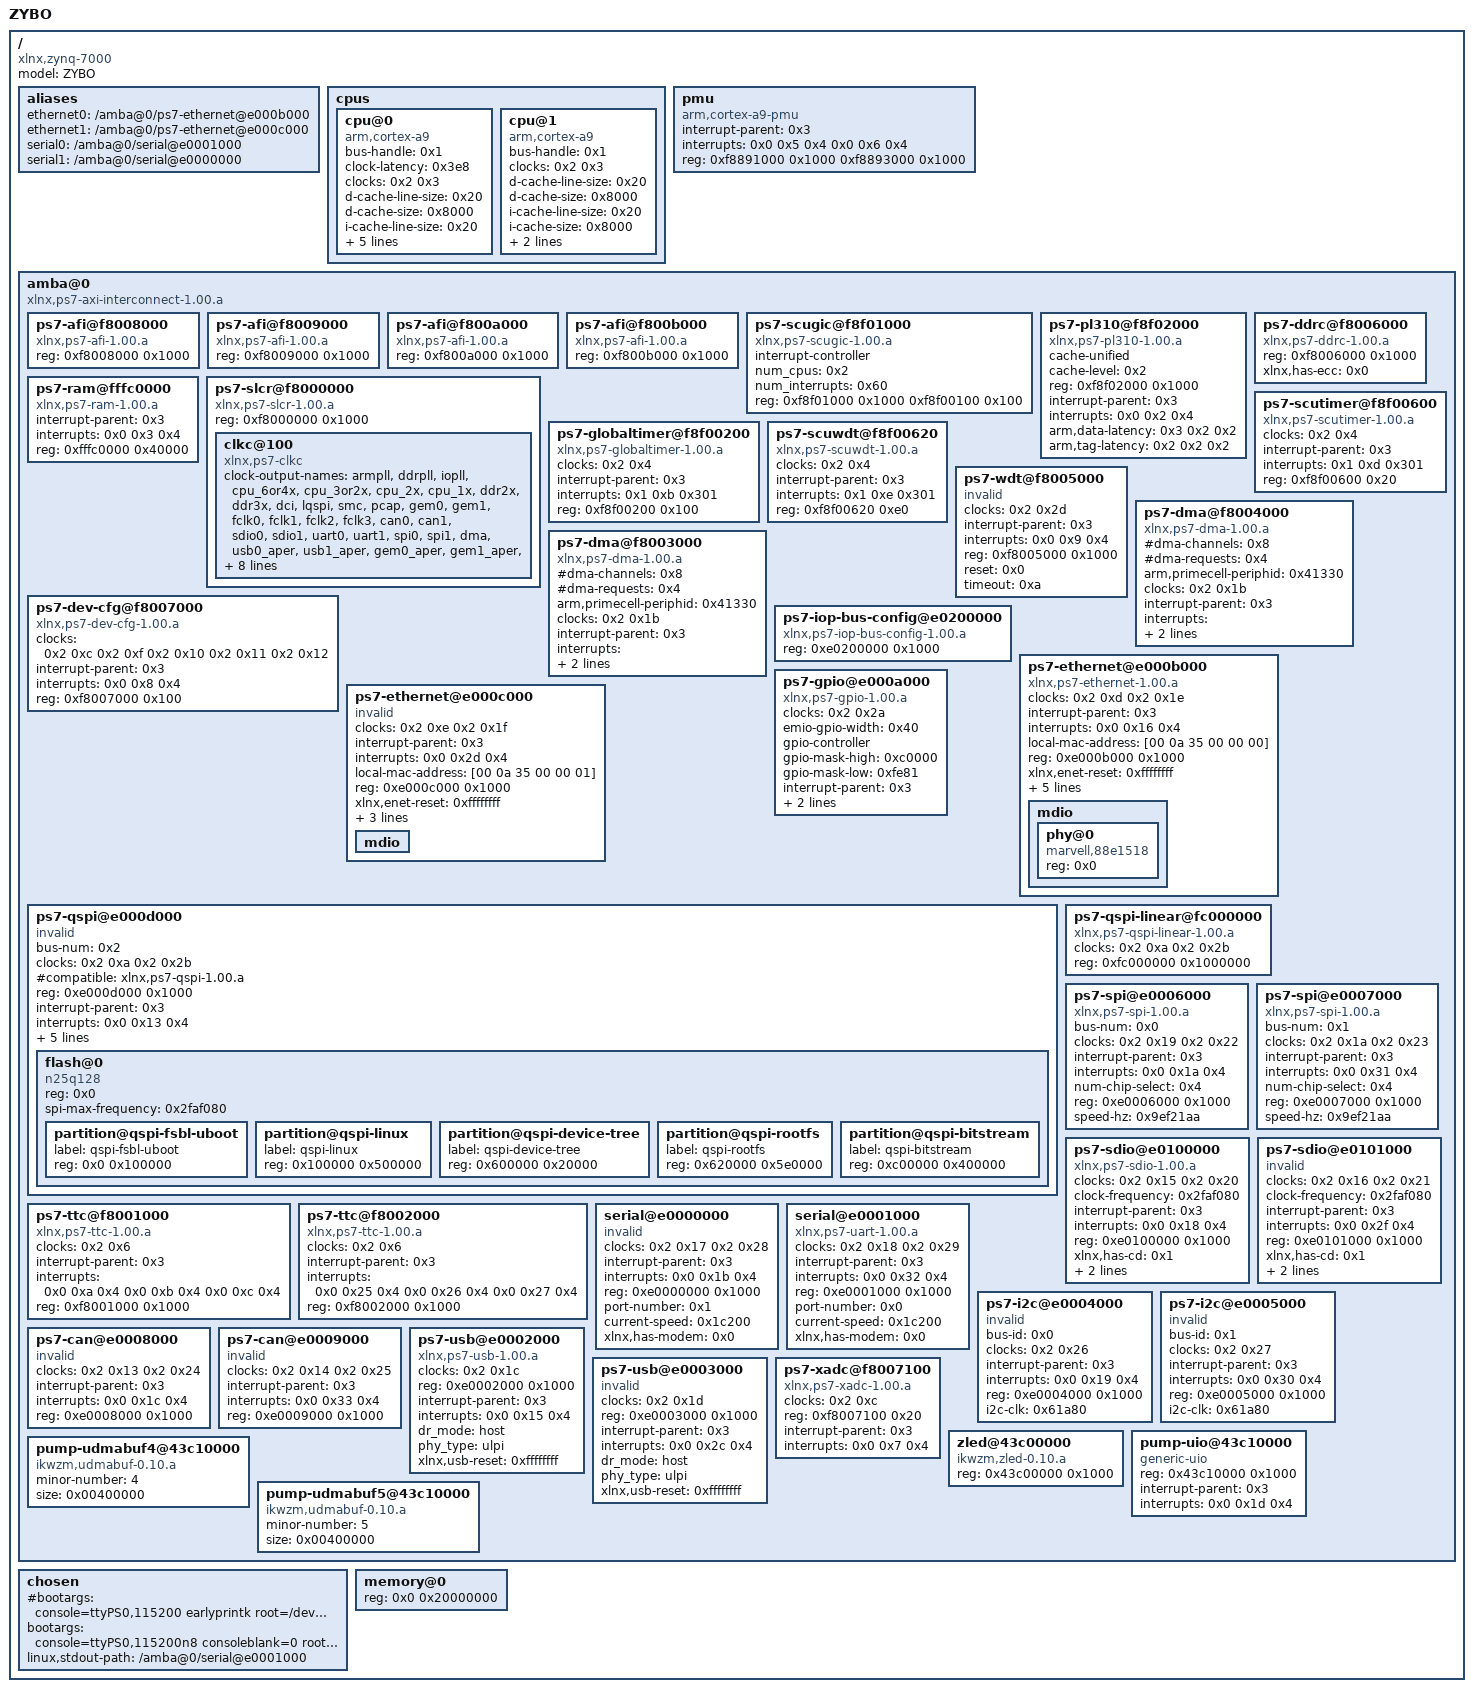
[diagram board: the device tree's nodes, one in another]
/dts-v1/;

/ {
	#address-cells = <0x1>;
	#size-cells = <0x1>;
	compatible = "xlnx,zynq-7000";
	model = "ZYBO";

	aliases {
		ethernet0 = "/amba@0/ps7-ethernet@e000b000";
		ethernet1 = "/amba@0/ps7-ethernet@e000c000";
		serial0 = "/amba@0/serial@e0001000";
		serial1 = "/amba@0/serial@e0000000";
	};

	cpus {
		#address-cells = <0x1>;
		#size-cells = <0x0>;

		cpu@0 {
			bus-handle = <0x1>;
			clock-latency = <0x3e8>;
			clocks = <0x2 0x3>;
			compatible = "arm,cortex-a9";
			d-cache-line-size = <0x20>;
			d-cache-size = <0x8000>;
			device_type = "cpu";
			i-cache-line-size = <0x20>;
			i-cache-size = <0x8000>;
			interrupt-handle = <0x3>;
			operating-points = <0xa2c2b 0xf4240 0x51616 0xf4240 0x3640f 0xf4240>;
			reg = <0x0>;
		};

		cpu@1 {
			bus-handle = <0x1>;
			clocks = <0x2 0x3>;
			compatible = "arm,cortex-a9";
			d-cache-line-size = <0x20>;
			d-cache-size = <0x8000>;
			device_type = "cpu";
			i-cache-line-size = <0x20>;
			i-cache-size = <0x8000>;
			interrupt-handle = <0x3>;
			reg = <0x1>;
		};
	};

	pmu {
		compatible = "arm,cortex-a9-pmu";
		interrupt-parent = <0x3>;
		interrupts = <0x0 0x5 0x4 0x0 0x6 0x4>;
		reg = <0xf8891000 0x1000 0xf8893000 0x1000>;
		reg-names = "cpu0", "cpu1";
	};

	amba@0 {
		#address-cells = <0x1>;
		#size-cells = <0x1>;
		compatible = "xlnx,ps7-axi-interconnect-1.00.a", "simple-bus";
		ranges;
		linux,phandle = <0x1>;
		phandle = <0x1>;

		ps7-afi@f8008000 {
			compatible = "xlnx,ps7-afi-1.00.a";
			reg = <0xf8008000 0x1000>;
		};

		ps7-afi@f8009000 {
			compatible = "xlnx,ps7-afi-1.00.a";
			reg = <0xf8009000 0x1000>;
		};

		ps7-afi@f800a000 {
			compatible = "xlnx,ps7-afi-1.00.a";
			reg = <0xf800a000 0x1000>;
		};

		ps7-afi@f800b000 {
			compatible = "xlnx,ps7-afi-1.00.a";
			reg = <0xf800b000 0x1000>;
		};

		ps7-scugic@f8f01000 {
			#address-cells = <0x2>;
			#interrupt-cells = <0x3>;
			#size-cells = <0x1>;
			compatible = "xlnx,ps7-scugic-1.00.a", "arm,cortex-a9-gic", "arm,gic";
			interrupt-controller;
			num_cpus = <0x2>;
			num_interrupts = <0x60>;
			reg = <0xf8f01000 0x1000 0xf8f00100 0x100>;
			linux,phandle = <0x3>;
			phandle = <0x3>;
		};

		ps7-pl310@f8f02000 {
			compatible = "xlnx,ps7-pl310-1.00.a", "arm,pl310-cache";
			cache-unified;
			cache-level = <0x2>;
			reg = <0xf8f02000 0x1000>;
			interrupt-parent = <0x3>;
			interrupts = <0x0 0x2 0x4>;
			arm,data-latency = <0x3 0x2 0x2>;
			arm,tag-latency = <0x2 0x2 0x2>;
		};

		ps7-ddrc@f8006000 {
			compatible = "xlnx,ps7-ddrc-1.00.a", "xlnx,ps7-ddrc";
			reg = <0xf8006000 0x1000>;
			xlnx,has-ecc = <0x0>;
		};

		ps7-ram@fffc0000 {
			compatible = "xlnx,ps7-ram-1.00.a", "xlnx,ps7-ocm";
			interrupt-parent = <0x3>;
			interrupts = <0x0 0x3 0x4>;
			reg = <0xfffc0000 0x40000>;
		};

		ps7-slcr@f8000000 {
			#address-cells = <0x1>;
			#size-cells = <0x1>;
			compatible = "xlnx,ps7-slcr-1.00.a", "xlnx,zynq-slcr", "syscon";
			ranges;
			reg = <0xf8000000 0x1000>;

			clkc@100 {
				#clock-cells = <0x1>;
				clock-output-names = "armpll", "ddrpll", "iopll", "cpu_6or4x", "cpu_3or2x", "cpu_2x", "cpu_1x", "ddr2x", "ddr3x", "dci", "lqspi", "smc", "pcap", "gem0", "gem1", "fclk0", "fclk1", "fclk2", "fclk3", "can0", "can1", "sdio0", "sdio1", "uart0", "uart1", "spi0", "spi1", "dma", "usb0_aper", "usb1_aper", "gem0_aper", "gem1_aper", "sdio0_aper", "sdio1_aper", "spi0_aper", "spi1_aper", "can0_aper", "can1_aper", "i2c0_aper", "i2c1_aper", "uart0_aper", "uart1_aper", "gpio_aper", "lqspi_aper", "smc_aper", "swdt", "dbg_trc", "dbg_apb";
				compatible = "xlnx,ps7-clkc";
				fclk-enable = <0xf>;
				ps-clk-frequency = <0x2faf080>;
				reg = <0x100 0x100>;
				linux,phandle = <0x2>;
				phandle = <0x2>;
			};
		};

		ps7-globaltimer@f8f00200 {
			clocks = <0x2 0x4>;
			compatible = "xlnx,ps7-globaltimer-1.00.a", "arm,cortex-a9-global-timer";
			interrupt-parent = <0x3>;
			interrupts = <0x1 0xb 0x301>;
			reg = <0xf8f00200 0x100>;
		};

		ps7-scutimer@f8f00600 {
			clocks = <0x2 0x4>;
			compatible = "xlnx,ps7-scutimer-1.00.a", "arm,cortex-a9-twd-timer";
			interrupt-parent = <0x3>;
			interrupts = <0x1 0xd 0x301>;
			reg = <0xf8f00600 0x20>;
		};

		ps7-scuwdt@f8f00620 {
			clocks = <0x2 0x4>;
			compatible = "xlnx,ps7-scuwdt-1.00.a";
			device_type = "watchdog";
			interrupt-parent = <0x3>;
			interrupts = <0x1 0xe 0x301>;
			reg = <0xf8f00620 0xe0>;
		};

		ps7-wdt@f8005000 {
			clocks = <0x2 0x2d>;
			compatible = "invalid";
			device_type = "watchdog";
			interrupt-parent = <0x3>;
			interrupts = <0x0 0x9 0x4>;
			reg = <0xf8005000 0x1000>;
			reset = <0x0>;
			timeout = <0xa>;
		};

		ps7-dma@f8004000 {
			#dma-cells = <0x1>;
			#dma-channels = <0x8>;
			#dma-requests = <0x4>;
			arm,primecell-periphid = <0x41330>;
			clock-names = "apb_pclk";
			clocks = <0x2 0x1b>;
			compatible = "xlnx,ps7-dma-1.00.a", "arm,primecell", "arm,pl330";
			interrupt-parent = <0x3>;
			interrupt-names = "abort", "dma0", "dma1", "dma2", "dma3", "dma4", "dma5", "dma6", "dma7";
			interrupts = <0x0 0xd 0x4 0x0 0xe 0x4 0x0 0xf 0x4 0x0 0x10 0x4 0x0 0x11 0x4 0x0 0x28 0x4 0x0 0x29 0x4 0x0 0x2a 0x4 0x0 0x2b 0x4>;
			reg = <0xf8004000 0x1000>;
		};

		ps7-dma@f8003000 {
			#dma-cells = <0x1>;
			#dma-channels = <0x8>;
			#dma-requests = <0x4>;
			arm,primecell-periphid = <0x41330>;
			clock-names = "apb_pclk";
			clocks = <0x2 0x1b>;
			compatible = "xlnx,ps7-dma-1.00.a", "arm,primecell", "arm,pl330";
			interrupt-parent = <0x3>;
			interrupt-names = "abort", "dma0", "dma1", "dma2", "dma3", "dma4", "dma5", "dma6", "dma7";
			interrupts = <0x0 0xd 0x4 0x0 0xe 0x4 0x0 0xf 0x4 0x0 0x10 0x4 0x0 0x11 0x4 0x0 0x28 0x4 0x0 0x29 0x4 0x0 0x2a 0x4 0x0 0x2b 0x4>;
			reg = <0xf8003000 0x1000>;
		};

		ps7-dev-cfg@f8007000 {
			clock-names = "ref_clk", "fclk0", "fclk1", "fclk2", "fclk3";
			clocks = <0x2 0xc 0x2 0xf 0x2 0x10 0x2 0x11 0x2 0x12>;
			compatible = "xlnx,ps7-dev-cfg-1.00.a";
			interrupt-parent = <0x3>;
			interrupts = <0x0 0x8 0x4>;
			reg = <0xf8007000 0x100>;
		};

		ps7-iop-bus-config@e0200000 {
			compatible = "xlnx,ps7-iop-bus-config-1.00.a";
			reg = <0xe0200000 0x1000>;
		};

		ps7-ethernet@e000b000 {
			#address-cells = <0x1>;
			#size-cells = <0x0>;
			clock-names = "ref_clk", "aper_clk";
			clocks = <0x2 0xd 0x2 0x1e>;
			compatible = "xlnx,ps7-ethernet-1.00.a";
			interrupt-parent = <0x3>;
			interrupts = <0x0 0x16 0x4>;
			local-mac-address = [00 0a 35 00 00 00];
			reg = <0xe000b000 0x1000>;
			xlnx,enet-reset = <0xffffffff>;
			xlnx,eth-mode = <0x1>;
			xlnx,has-mdio = <0x1>;
			xlnx,ptp-enet-clock = <0x69f6bcb>;
			phy-handle = <0x4>;
			phy-mode = "rgmii-id";

			mdio {
				#address-cells = <0x1>;
				#size-cells = <0x0>;

				phy@0 {
					compatible = "marvell,88e1518";
					device_type = "ethernet-phy";
					reg = <0x0>;
					linux,phandle = <0x4>;
					phandle = <0x4>;
				};
			};
		};

		ps7-ethernet@e000c000 {
			#address-cells = <0x1>;
			#size-cells = <0x0>;
			clock-names = "ref_clk", "aper_clk";
			clocks = <0x2 0xe 0x2 0x1f>;
			compatible = "invalid";
			interrupt-parent = <0x3>;
			interrupts = <0x0 0x2d 0x4>;
			local-mac-address = [00 0a 35 00 00 01];
			reg = <0xe000c000 0x1000>;
			xlnx,enet-reset = <0xffffffff>;
			xlnx,eth-mode = <0x1>;
			xlnx,has-mdio = <0x1>;
			xlnx,ptp-enet-clock = <0x69f6bcb>;

			mdio {
				#address-cells = <0x1>;
				#size-cells = <0x0>;
			};
		};

		ps7-gpio@e000a000 {
			#gpio-cells = <0x2>;
			clocks = <0x2 0x2a>;
			compatible = "xlnx,ps7-gpio-1.00.a";
			emio-gpio-width = <0x40>;
			gpio-controller;
			gpio-mask-high = <0xc0000>;
			gpio-mask-low = <0xfe81>;
			interrupt-parent = <0x3>;
			interrupts = <0x0 0x14 0x4>;
			reg = <0xe000a000 0x1000>;
		};

		ps7-qspi@e000d000 {
			bus-num = <0x2>;
			clock-names = "ref_clk", "aper_clk";
			clocks = <0x2 0xa 0x2 0x2b>;
			#compatible = "xlnx,ps7-qspi-1.00.a";
			compatible = "invalid";
			reg = <0xe000d000 0x1000>;
			interrupt-parent = <0x3>;
			interrupts = <0x0 0x13 0x4>;
			is-dual = <0x0>;
			num-chip-select = <0x1>;
			speed-hz = <0xbebc200>;
			xlnx,fb-clk = <0x1>;
			xlnx,qspi-mode = <0x0>;
			#address-cells = <0x1>;
			#size-cells = <0x0>;

			flash@0 {
				compatible = "n25q128";
				reg = <0x0>;
				spi-max-frequency = <0x2faf080>;
				#address-cells = <0x1>;
				#size-cells = <0x1>;

				partition@qspi-fsbl-uboot {
					label = "qspi-fsbl-uboot";
					reg = <0x0 0x100000>;
				};

				partition@qspi-linux {
					label = "qspi-linux";
					reg = <0x100000 0x500000>;
				};

				partition@qspi-device-tree {
					label = "qspi-device-tree";
					reg = <0x600000 0x20000>;
				};

				partition@qspi-rootfs {
					label = "qspi-rootfs";
					reg = <0x620000 0x5e0000>;
				};

				partition@qspi-bitstream {
					label = "qspi-bitstream";
					reg = <0xc00000 0x400000>;
				};
			};
		};

		ps7-qspi-linear@fc000000 {
			clock-names = "ref_clk", "aper_clk";
			clocks = <0x2 0xa 0x2 0x2b>;
			compatible = "xlnx,ps7-qspi-linear-1.00.a";
			reg = <0xfc000000 0x1000000>;
		};

		ps7-spi@e0006000 {
			bus-num = <0x0>;
			clock-names = "ref_clk", "aper_clk";
			clocks = <0x2 0x19 0x2 0x22>;
			compatible = "xlnx,ps7-spi-1.00.a";
			interrupt-parent = <0x3>;
			interrupts = <0x0 0x1a 0x4>;
			num-chip-select = <0x4>;
			reg = <0xe0006000 0x1000>;
			speed-hz = <0x9ef21aa>;
			#address-cells = <0x1>;
			#size-cells = <0x0>;
		};

		ps7-spi@e0007000 {
			bus-num = <0x1>;
			clock-names = "ref_clk", "aper_clk";
			clocks = <0x2 0x1a 0x2 0x23>;
			compatible = "xlnx,ps7-spi-1.00.a";
			interrupt-parent = <0x3>;
			interrupts = <0x0 0x31 0x4>;
			num-chip-select = <0x4>;
			reg = <0xe0007000 0x1000>;
			speed-hz = <0x9ef21aa>;
			#address-cells = <0x1>;
			#size-cells = <0x0>;
		};

		ps7-sdio@e0100000 {
			clock-names = "ref_clk", "aper_clk";
			clocks = <0x2 0x15 0x2 0x20>;
			clock-frequency = <0x2faf080>;
			compatible = "xlnx,ps7-sdio-1.00.a", "arasan,sdhci", "arasan,sdhci-8.9a", "generic-sdhci";
			interrupt-parent = <0x3>;
			interrupts = <0x0 0x18 0x4>;
			reg = <0xe0100000 0x1000>;
			xlnx,has-cd = <0x1>;
			xlnx,has-power = <0x0>;
			xlnx,has-wp = <0x1>;
		};

		ps7-sdio@e0101000 {
			clock-names = "ref_clk", "aper_clk";
			clocks = <0x2 0x16 0x2 0x21>;
			clock-frequency = <0x2faf080>;
			compatible = "invalid";
			interrupt-parent = <0x3>;
			interrupts = <0x0 0x2f 0x4>;
			reg = <0xe0101000 0x1000>;
			xlnx,has-cd = <0x1>;
			xlnx,has-power = <0x0>;
			xlnx,has-wp = <0x1>;
		};

		ps7-ttc@f8001000 {
			clocks = <0x2 0x6>;
			compatible = "xlnx,ps7-ttc-1.00.a", "cdns,ttc";
			interrupt-names = "ttc0", "ttc1", "ttc2";
			interrupt-parent = <0x3>;
			interrupts = <0x0 0xa 0x4 0x0 0xb 0x4 0x0 0xc 0x4>;
			reg = <0xf8001000 0x1000>;
		};

		ps7-ttc@f8002000 {
			clocks = <0x2 0x6>;
			compatible = "xlnx,ps7-ttc-1.00.a", "cdns,ttc";
			interrupt-names = "ttc0", "ttc1", "ttc2";
			interrupt-parent = <0x3>;
			interrupts = <0x0 0x25 0x4 0x0 0x26 0x4 0x0 0x27 0x4>;
			reg = <0xf8002000 0x1000>;
		};

		serial@e0000000 {
			clock-names = "ref_clk", "aper_clk";
			clocks = <0x2 0x17 0x2 0x28>;
			compatible = "invalid";
			device_type = "serial";
			interrupt-parent = <0x3>;
			interrupts = <0x0 0x1b 0x4>;
			reg = <0xe0000000 0x1000>;
			port-number = <0x1>;
			current-speed = <0x1c200>;
			xlnx,has-modem = <0x0>;
		};

		serial@e0001000 {
			clock-names = "ref_clk", "aper_clk";
			clocks = <0x2 0x18 0x2 0x29>;
			compatible = "xlnx,ps7-uart-1.00.a", "xlnx,xuartps";
			device_type = "serial";
			interrupt-parent = <0x3>;
			interrupts = <0x0 0x32 0x4>;
			reg = <0xe0001000 0x1000>;
			port-number = <0x0>;
			current-speed = <0x1c200>;
			xlnx,has-modem = <0x0>;
		};

		ps7-i2c@e0004000 {
			bus-id = <0x0>;
			clocks = <0x2 0x26>;
			compatible = "invalid";
			interrupt-parent = <0x3>;
			interrupts = <0x0 0x19 0x4>;
			reg = <0xe0004000 0x1000>;
			i2c-clk = <0x61a80>;
			#address-cells = <0x1>;
			#size-cells = <0x0>;
		};

		ps7-i2c@e0005000 {
			bus-id = <0x1>;
			clocks = <0x2 0x27>;
			compatible = "invalid";
			interrupt-parent = <0x3>;
			interrupts = <0x0 0x30 0x4>;
			reg = <0xe0005000 0x1000>;
			i2c-clk = <0x61a80>;
			#address-cells = <0x1>;
			#size-cells = <0x0>;
		};

		ps7-can@e0008000 {
			clock-names = "ref_clk", "aper_clk";
			clocks = <0x2 0x13 0x2 0x24>;
			compatible = "invalid";
			interrupt-parent = <0x3>;
			interrupts = <0x0 0x1c 0x4>;
			reg = <0xe0008000 0x1000>;
		};

		ps7-can@e0009000 {
			clock-names = "ref_clk", "aper_clk";
			clocks = <0x2 0x14 0x2 0x25>;
			compatible = "invalid";
			interrupt-parent = <0x3>;
			interrupts = <0x0 0x33 0x4>;
			reg = <0xe0009000 0x1000>;
		};

		ps7-usb@e0002000 {
			clocks = <0x2 0x1c>;
			compatible = "xlnx,ps7-usb-1.00.a", "xlnx,zynq-usb-1.00.a";
			reg = <0xe0002000 0x1000>;
			interrupt-parent = <0x3>;
			interrupts = <0x0 0x15 0x4>;
			dr_mode = "host";
			phy_type = "ulpi";
			xlnx,usb-reset = <0xffffffff>;
		};

		ps7-usb@e0003000 {
			clocks = <0x2 0x1d>;
			compatible = "invalid";
			reg = <0xe0003000 0x1000>;
			interrupt-parent = <0x3>;
			interrupts = <0x0 0x2c 0x4>;
			dr_mode = "host";
			phy_type = "ulpi";
			xlnx,usb-reset = <0xffffffff>;
		};

		ps7-xadc@f8007100 {
			clocks = <0x2 0xc>;
			compatible = "xlnx,ps7-xadc-1.00.a";
			reg = <0xf8007100 0x20>;
			interrupt-parent = <0x3>;
			interrupts = <0x0 0x7 0x4>;
		};

		zled@43c00000 {
			compatible = "ikwzm,zled-0.10.a";
			reg = <0x43c00000 0x1000>;
                };

		pump-uio@43c10000 {
			compatible = "generic-uio";
			reg = <0x43c10000 0x1000>;
			interrupt-parent = <0x3>;
			interrupts = <0x0 0x1d 0x4>;
                };

		pump-udmabuf4@43c10000 {
			compatible = "ikwzm,udmabuf-0.10.a";
			minor-number = <4>;
			size = <0x00400000>;
                };

		pump-udmabuf5@43c10000 {
			compatible = "ikwzm,udmabuf-0.10.a";
			minor-number = <5>;
			size = <0x00400000>;
                };

	};

	chosen {
		#bootargs = "console=ttyPS0,115200 earlyprintk root=/dev/ram rw";
		bootargs = "console=ttyPS0,115200n8 consoleblank=0 root=/dev/mmcblk0p2 rw rootwait earlyprintk";
		linux,stdout-path = "/amba@0/serial@e0001000";
	};

	memory@0 {
		device_type = "memory";
		reg = <0x0 0x20000000>;
	};
};
